# max78002 register map
Vendor: Maxim-Integrated; Series: ARMCM4; File version: 1.1
CPU: CM4 r2p1, little endian, MPU, FPU, 3 interrupt priority bits
Registers are 32-bit, read-write, reset 0x0 unless marked. A register's access mark holds for its fields unless they carry their own. Offsets are from the block's base; [hi:lo] are bit positions.

## SIR — System Initialization Registers.
Base 0x40000400
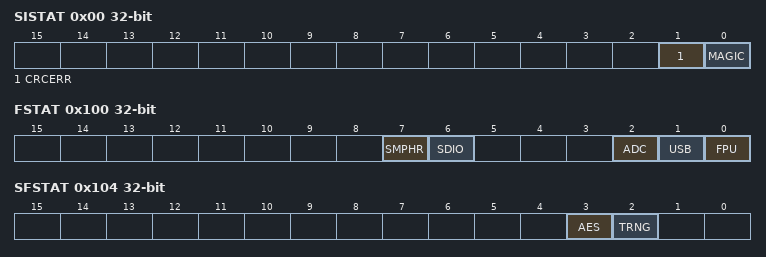
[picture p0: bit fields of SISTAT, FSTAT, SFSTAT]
0x00 SISTAT ro — System Initialization Status Register.
  [1] CRCERR — CRC Error Status. This bit is set by the system initialization block following power-up.
    on read: 0=noError (No CRC errors occurred during the read of the OTP memory block.); 1=error (A CRC error occurred while reading the OTP. The address of the failure location in the OTP memory is stored in the ERRADDR register.)
  [0] MAGIC — Magic Word Validation. This bit is set by the system initialization block following power-up.
    on read: 0=magicNotSet (Magic word was not set (OTP has not been initialized properly).); 1=magicSet (Magic word was set (OTP contains valid settings).)
0x04 SIADDR ro — Read-only field set by the SIB block if a CRC error occurs during the read of the OTP memory. Contains the failing address in OTP memory (when CRCERR equals 1).
  [31:0] ERRADDR
0x100 FSTAT ro — funcstat register.
  [all] fields
    0=no; 1=yes
  [7] SMPHR — SMPHR function.
  [6] SDIO — SDIO Function.
  [2] ADC — ADC Function.
  [1] USB — USB Function.
  [0] FPU — FPU Function.
0x104 SFSTAT ro — Security function status register.
  [3] AES — AES Block.
    0=no; 1=yes
  [2] TRNG — TRNG Function.
    0=no; 1=yes

## TRNG — Random Number Generator.
Base 0x4004D000
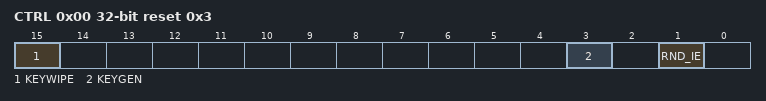
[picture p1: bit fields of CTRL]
0x00 CTRL reset 0x3 — TRNG Control Register.
  [15] KEYWIPE — To wipe the Battery Backed key.
  [3] KEYGEN — AES Key Generate. When enabled, the key for securing NVSRAM is generated and transferred to the secure key register automatically without user visibility or intervention. This bit is cleared by hardware once the key has been transferred to the secure key register.
  [1] RND_IE — To enable IRQ generation when a new 32-bit Random number is ready.
    0=disable; 1=enable
0x04 STATUS — Data. The content of this register is valid only when RNG_IS = 1. When TRNG is disabled, read returns 0x0000 0000.
  [0] RDY — 32-bit random data is ready to read from TRNG_DATA register. Reading TRNG_DATA when RND_RDY=0 will return all 0's. IRQ is generated when RND_RDY=1 if TRNG_CN.RND_IRQ_EN=1.
    0=Busy (TRNG Busy); 1=Ready (32 bit random data is ready)
0x08 DATA ro — Data. The content of this register is valid only when RNG_IS = 1. When TRNG is disabled, read returns 0x0000 0000.
  [31:0] DATA — Data. The content of this register is valid only when RNG_IS =1. When TNRG is disabled, read returns 0x0000 0000.

## TRIMSIR — Trim System Initilazation Registers
Base 0x40005400
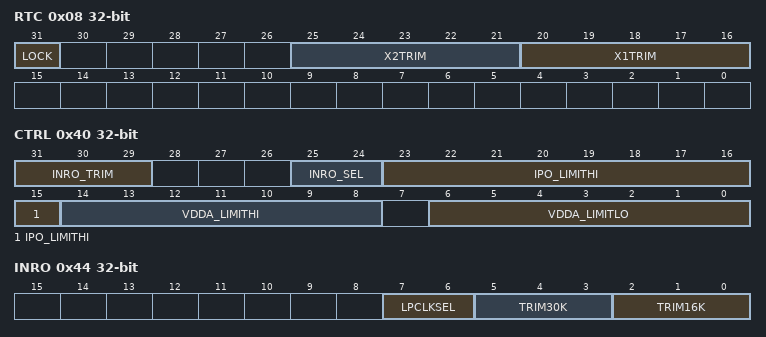
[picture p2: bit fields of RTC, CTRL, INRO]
0x08 RTC — RTC Trim System Initialization Register.
  [31] LOCK
  [25:21] X2TRIM — RTC X2 Trim.
  [20:16] X1TRIM — RTC X1 Trim.
0x34 SIMO ro — SIMO Trim System Initialization Register.
  [2:0] CLKDIV — SIMO Clock Divide.
    0=DIV1; 1=DIV16; 3=DIV32; 5=DIV64; 7=DIV128
0x3C IPOLO ro — IPO Low Trim System Initialization Register.
  [7:0] IPO_LIMITLO — IPO Low Limit Trim.
0x40 CTRL — Control Trim System Initialization Register.
  [31:29] INRO_TRIM — INRO Clock Trim.
  [25:24] INRO_SEL — INRO Clock Select.
    0=8KHZ; 1=16KHZ; 2=30KHZ
  [23:15] IPO_LIMITHI — IPO High Trim Limit.
  [14:8] VDDA_LIMITHI — VDDA High Trim Limit.
  [6:0] VDDA_LIMITLO — VDDA Low Trim Limit.
0x44 INRO — RTC Trim System Initialization Register.
  [7:6] LPCLKSEL — INRO Low Power Mode Clock Select.
    0=8KHZ; 1=16KHZ; 2=30KHZ
  [5:3] TRIM30K — INRO 30KHz Trim.
  [2:0] TRIM16K — INRO 16KHz Trim.

## WUT — Wake Up Timer
Base 0x40006400
0x00 CNT — Wakeup Timer Count Register
  [31:0] COUNT — Timer Count Value.
0x04 CMP — Wakeup Timer Compare Register
  [31:0] COMPARE — Timer Compare Value.
0x0C INTFL — Wakeup Timer Interrupt Register
  [0] IRQ_CLR — Timer Interrupt.
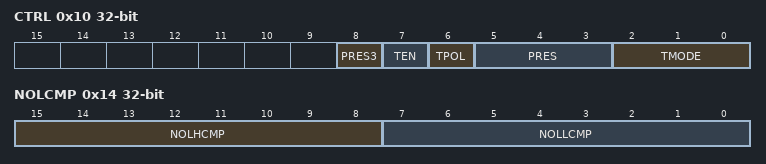
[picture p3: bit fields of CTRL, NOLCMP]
0x10 CTRL — Wakeup Timer Control Register
  [8] PRES3 — Timer Prescaler Select.
    0=pres3_1; 0=pres3_2; 0=pres3_4; 0=pres3_8; 0=pres3_16; 0=pres3_32; 0=pres3_64; 0=pres3_128; 1=pres3_256; 1=pres3_512; 1=pres3_1024; 1=pres3_2048; 1=pres3_4096
  [7] TEN — Timer Enable.
    0=timer_dis; 1=timer_en
  [6] TPOL — Timer pOLARITY.
  [5:3] PRES — Timer Prescaler Select.
    0=DIV1; 1=DIV2; 2=DIV4; 3=DIV8; 4=DIV16; 5=DIV32; 6=DIV64; 7=DIV128; 0=DIV256; 2=DIV512; 3=DIV1024; 4=DIV2048; 5=DIV4096
  [2:0] TMODE — Timer Mode Select.
    0=One Shot Mode; 1=Continuous Mode; 2=Counter Mode; 3=pwm (PWM Mode.); 4=Capture Mode; 5=Compare Mode; 6=Gated Mode; 7=Capture/Compare Mode
0x14 NOLCMP — Non Overlaping Compare Register
  [15:8] NOLHCMP — Non Overlaping High Compare.
  [7:0] NOLLCMP — Non Overlaping Low Compare.
0x18 PRESET
  [31:0] PRESET — Preset Value.
0x1C RELOAD
  [31:0] RELOAD — Reload Value.
0x20 SNAPSHOT
  [31:0] SNAPSHOT — Snapshot Value.
